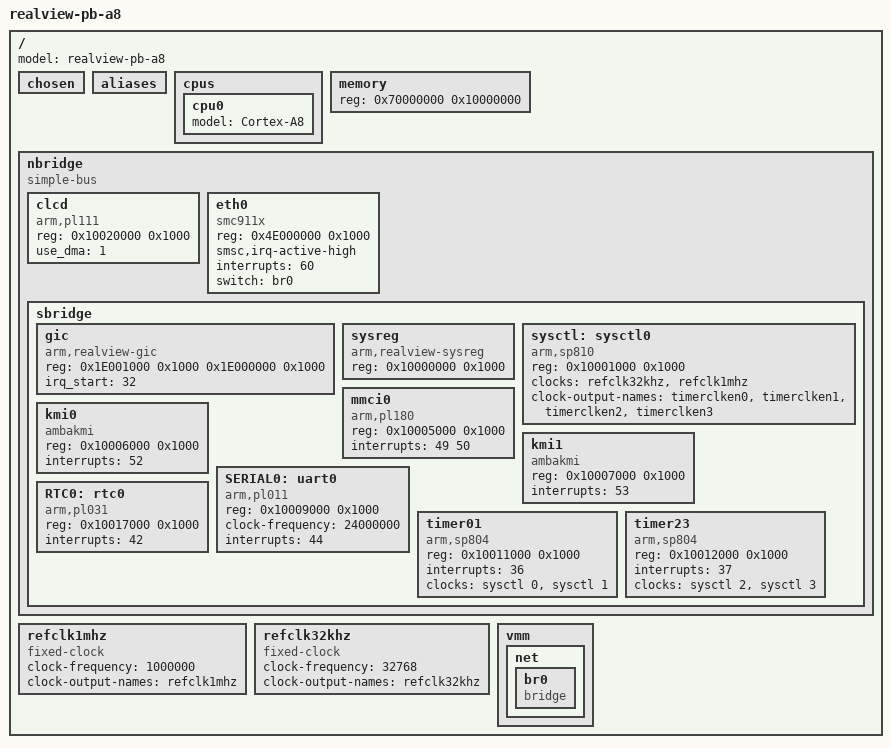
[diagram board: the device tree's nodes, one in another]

/ {
	#address-cells = <1>;
	#size-cells = <1>;
	model = "realview-pb-a8";

	chosen { };
	aliases { };

	cpus {
		cpu0 {
			device_type = "cpu";
			model = "Cortex-A8";
		};
	};

	memory {
		device_type = "memory"; 
		reg = <0x70000000 0x10000000>; /* 256 MB */
	};

	nbridge {
		#address-cells = <1>;
		#size-cells = <1>;
		compatible = "simple-bus";

		clcd {
	      		device_type = "fb";
	      		compatible = "arm,pl111";
	      		reg = <0x10020000 0x1000>;
			use_dma = <1>;
		};

		eth0 {
			device_type = "nic";
			compatible = "smc911x";
			reg = <0x4E000000 0x1000>;
			smsc,irq-active-high;
			interrupts = <60>;
			switch = "br0";
		};

		sbridge {
			#address-cells = <1>;
			#size-cells = <1>;

			gic { /* Generic Interrupt Controller */
		      		device_type = "pic";
		      		compatible = "arm,realview-gic";
		      		reg = <0x1E001000 0x1000
				       0x1E000000 0x1000>;
				irq_start = <32>;
			};

			sysreg { /* System Registers */
		      		device_type = "sys";
		      		compatible = "arm,realview-sysreg";
		      		reg = <0x10000000 0x1000>;
			};

			sysctl: sysctl0 { /* System Controller */
		      		device_type = "sys";
		      		compatible = "arm,sp810";
		      		reg = <0x10001000 0x1000>;
				clocks = <&refclk32khz>, <&refclk1mhz>;
				clock-names = "refclk", "timclk", "apb_pclk";
				#clock-cells = <1>;
				clock-output-names = "timerclken0", "timerclken1", "timerclken2", "timerclken3";
			};

			mmci0 { /* Multimedia Card Interface */
		      		device_type = "mmc";
		      		compatible = "arm,pl180";
		      		reg = <0x10005000 0x1000>;
				interrupts = <49 50>;
			};

			kmi0 { /* Keyboard */
		      		device_type = "serio";
		      		compatible = "ambakmi";
		      		reg = <0x10006000 0x1000>;
				interrupts = <52>;
			};

			kmi1 { /* Mouse */
		      		device_type = "serio";
		      		compatible = "ambakmi";
		      		reg = <0x10007000 0x1000>;
				interrupts = <53>;
			};

			SERIAL0: uart0 {
		      		compatible = "arm,pl011";
		      		reg = <0x10009000 0x1000>;
				clock-frequency = <24000000>;
				interrupts = <44>;
			};

			timer01 {
		      		device_type = "timer";
		      		compatible = "arm,sp804";
		      		reg = <0x10011000 0x1000>;
				interrupts = <36>;
				clocks = <&sysctl 0>, <&sysctl 1>;
				clock-names = "timclken1", "timclken2";
			};

			timer23 {
		      		device_type = "timer";
		      		compatible = "arm,sp804";
		      		reg = <0x10012000 0x1000>;
				interrupts = <37>;
				clocks = <&sysctl 2>, <&sysctl 3>;
				clock-names = "timclken1", "timclken2";
			};

			RTC0: rtc0 {
		      		device_type = "rtc";
		      		compatible = "arm,pl031";
		      		reg = <0x10017000 0x1000>;
				interrupts = <42>;
			};
		};
	};

	refclk1mhz: refclk1mhz {
		compatible = "fixed-clock";
		#clock-cells = <0>;
		clock-frequency = <1000000>;
		clock-output-names = "refclk1mhz";
	};

	refclk32khz: refclk32khz {
		compatible = "fixed-clock";
		#clock-cells = <0>;
		clock-frequency = <32768>;
		clock-output-names = "refclk32khz";
	};

	vmm {
		net {
			br0 {
				device_type = "netswitch";
				compatible = "bridge";
			};
		};
	};
};

/* Add guest templates */
/include/ "../../../common/guests/realview-pb-a8.dtsi"
/include/ "../../../common/guests/vexpress-a9x2.dtsi"

